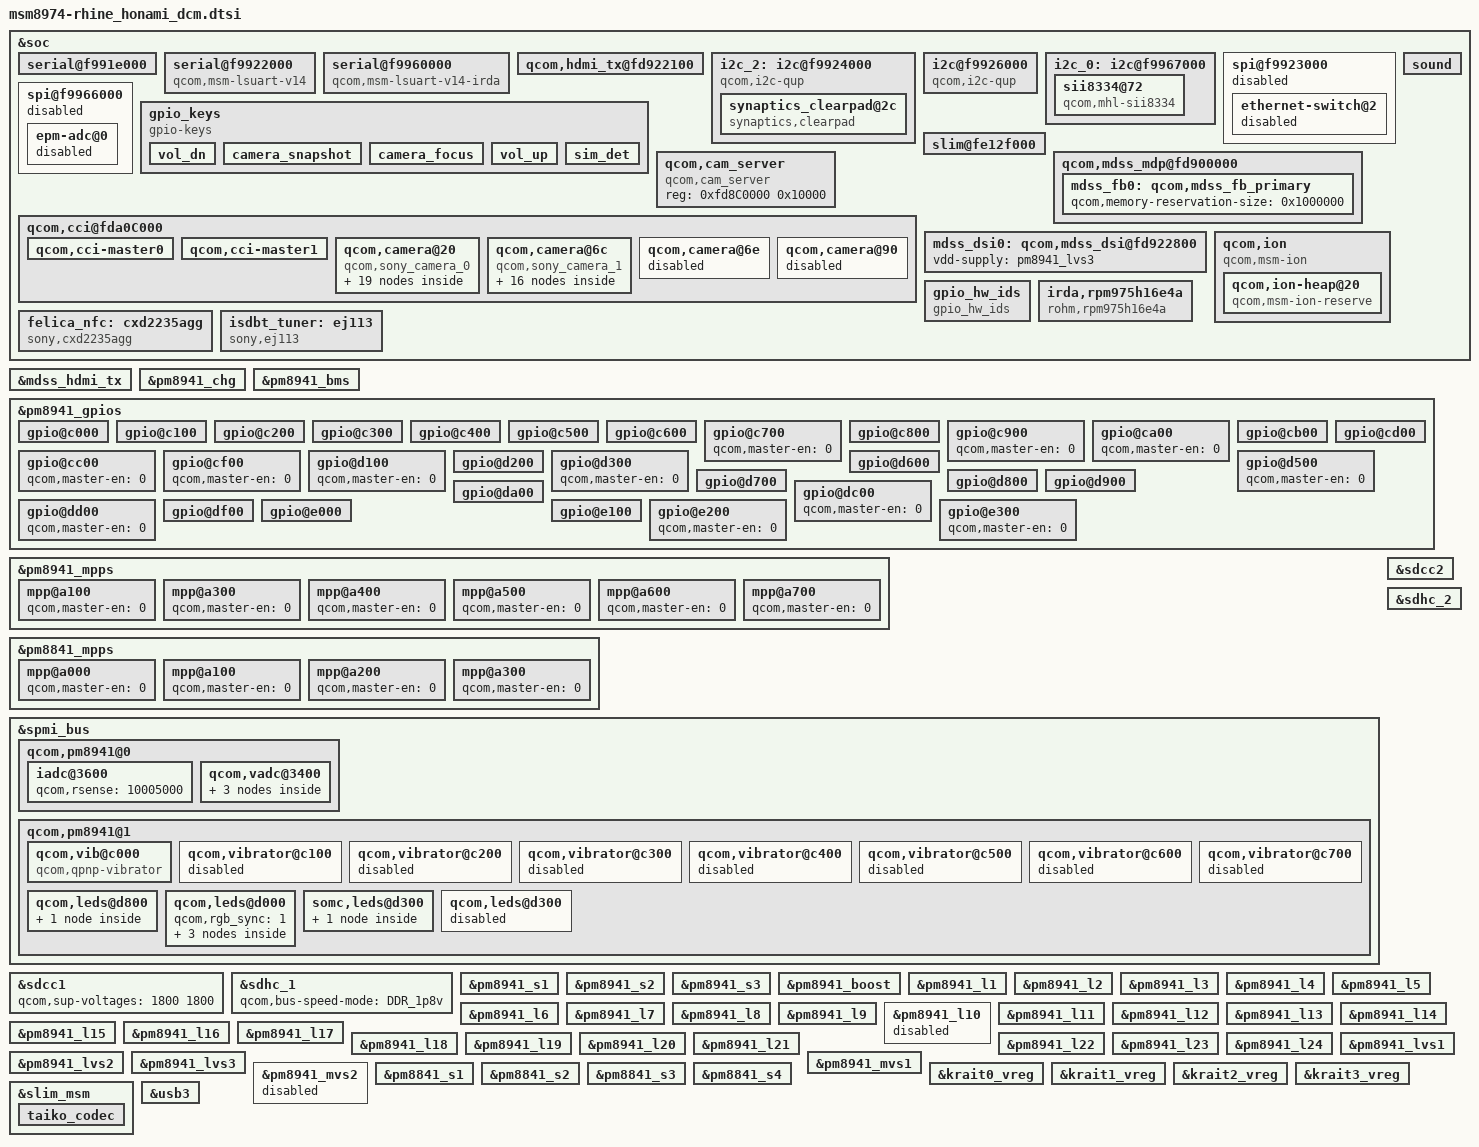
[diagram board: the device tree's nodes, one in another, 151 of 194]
/* arch/arm/boot/dts/msm8974-rhine_honami_dcm.dtsi
 *
 * Copyright (C) 2013 Sony Mobile Communications AB.
 *
 * Author: Yukito Naganuma <Yukito.X.Naganuma@sonymobile.com>
 *
 * This program is free software; you can redistribute it and/or modify
 * it under the terms of the GNU General Public License version 2 and
 * only version 2 as published by the Free Software Foundation.
 *
 * This program is distributed in the hope that it will be useful,
 * but WITHOUT ANY WARRANTY; without even the implied warranty of
 * MERCHANTABILITY or FITNESS FOR A PARTICULAR PURPOSE.  See the
 * GNU General Public License for more details.
 */

&soc {
	/* BLSP1-1 */
	serial@f991e000 {
		status = "ok";
	};

	/* BLSP1-5 */
	serial@f9922000 {
		compatible = "qcom,msm-lsuart-v14";
		reg = <0xf9922000 0x1000>;
		interrupts = <0 112 0>;		/* temporary: interrupt ID is correct??? */
		status = "ok";
	};

	/* BLSP2-3 */
	serial@f9960000 {
		compatible = "qcom,msm-lsuart-v14-irda";
		reg = <0xf9960000 0x1000>;
		interrupts = <0 116 0>;		/* temporary: interrupt ID is correct??? */
		status = "ok";
	};

	qcom,hdmi_tx@fd922100 {
		status = "ok";
	};

	/* BLSP1-1 */
	i2c_2: i2c@f9924000 {
		cell-index = <0>;
		compatible = "qcom,i2c-qup";
		qcom,i2c-bus-freq = <355000>;
		qcom,scl-gpio = <&msmgpio 7 0x00>;
		qcom,sda-gpio = <&msmgpio 6 0x00>;
		status = "ok";
		synaptics_clearpad@2c {
			compatible = "synaptics,clearpad";
			reg = <0x2c>;
			interrupt-parent = <&msmgpio>;
			interrupts = <61 0x2>;
			touch_vdd-supply = <&pm8941_l22>;
			touch_vio-supply = <&pm8941_s3>;
			synaptics,irq_gpio = <&msmgpio 61 0x00>;
			pen_enabled = <0>;
			preset_x_max = <1079>;
			preset_y_max = <1919>;
			preset_n_fingers = <10>;
			preset_n_bytes_per_object = <8>;
			por_delay_after = <200>;
		};
	};

	/* BLSP1-3 */
	i2c@f9926000 {
		cell-index = <1>;
		compatible = "qcom,i2c-qup";
		reg = <0xf9926000 0x1000>;
		#address-cells = <1>;
		#size-cells = <0>;
		reg-names = "qup_phys_addr";
		interrupts = <0 98 0>;
		interrupt-names = "qup_err_intr";
		qcom,i2c-bus-freq = <355000>;
		qcom,i2c-src-freq = <50000000>;
		qcom,master-id = <86>;
		status = "ok";
	};

	/* BLSP2-4 */
	i2c_0: i2c@f9967000 {
		cell-index = <4>;
		qcom,i2c-bus-freq = <355000>;
		status = "ok";
		sii8334@72 {
			compatible = "qcom,mhl-sii8334";
			reg = <0x72>;
			interrupt-parent = <&msmgpio>;
			interrupts = <64 0x2008>;
			mhl-intr-gpio = <&msmgpio 64 0>;
			mhl-pwr-gpio = <&msmgpio 60 0>;
			mhl-rst-gpio = <&msmgpio 16 0>;
			qcom,hdmi-tx-map = <&mdss_hdmi_tx>;
		};
	};

	spi@f9923000 {
		status = "disabled";
		ethernet-switch@2 {
			status = "disabled";
		};
	};

	spi@f9966000 {
		status = "disabled";
		epm-adc@0 {
			status = "disabled";
		};
	};

	gpio_keys {
		compatible = "gpio-keys";
		input-name = "gpio-keys";
		interrupt-parent = <&msmgpio>;
		interrupts = <9 0>;

		vol_dn {
			label = "volume_down";
			gpios = <&pm8941_gpios 2 0x1>;
			linux,input-type = <1>;
			linux,code = <114>;
			gpio-key,wakeup;
			debounce-interval = <15>;
		};

		camera_snapshot {
			label = "camera_snapshot";
			gpios = <&pm8941_gpios 3 0x1>;
			linux,input-type = <1>;
			linux,code = <0x2fe>;
			gpio-key,wakeup;
			debounce-interval = <15>;
		};

		camera_focus {
			label = "camera_focus";
			gpios = <&pm8941_gpios 4 0x1>;
			linux,input-type = <1>;
			linux,code = <0x210>;
			gpio-key,wakeup;
			debounce-interval = <15>;
		};

		vol_up {
			label = "volume_up";
			gpios = <&pm8941_gpios 5 0x1>;
			linux,input-type = <1>;
			linux,code = <115>;
			gpio-key,wakeup;
			debounce-interval = <15>;
		};

		sim_det {
			label = "sim-detection";
			gpios = <&msmgpio 9 0x0>;
			linux,input-type = <5>;
			linux,code = <7>;
			gpio-key,wakeup;
			debounce-interval = <10>;
		};
	};

	slim@fe12f000 {
		/* should be added for eS325 settings? same as taiko_codec? */
		/* or place settings on kernel code? */
	};

	qcom,cam_server {
		compatible = "qcom,cam_server";
		reg = <0xfd8C0000 0x10000>;
		reg-names = "server";
	};

	qcom,cci@fda0C000 {
		qcom,cci-master0 {
			qcom,hw-thigh = <22>;
			qcom,hw-tlow = <33>;
		};

		qcom,cci-master1 {
			qcom,hw-thigh = <22>;
			qcom,hw-tlow = <33>;
		};

		qcom,camera@20 {
			compatible = "qcom,sony_camera_0";
			reg = <0x20 0x0>;
			status = "ok";
			qcom,slave-id = <0x20 0x0 0x0000>;
			qcom,csiphy-sd-index = <0>;
			qcom,csid-sd-index = <0>;
			qcom,mount-angle = <270>;
			qcom,sensor-name = "sony_camera_0";
			cam_vdig-supply = <&pm8941_l3>;
			cam_vana-supply = <&pm8941_l17>;
			cam_vio-supply = <&pm8941_lvs2>;
			cam_vaf-supply = <&pm8941_l23>;
			qcom,cam-vreg-name = "cam_vdig", "cam_vana", "cam_vio",
					     "cam_vaf";
			qcom,cam-vreg-type = <0 0 1 0>;
			qcom,cam-vreg-min-voltage = <1200000 2700000 0 2800000>;
			qcom,cam-vreg-max-voltage = <1200000 2700000 0 2800000>;
			qcom,cam-vreg-op-mode = <105000 85600 0 300000>;
			qcom,gpio-no-mux = <0>;
			gpios = <&msmgpio 15 0>,
				<&msmgpio 94 0>;
			qcom,gpio-reset = <1>;
			qcom,gpio-req-tbl-num = <0 1>;
			qcom,gpio-req-tbl-flags = <1 0>;
			qcom,gpio-req-tbl-label = "CAMIF_MCLK",
						  "CAM_RESET1";
			qcom,gpio-set-tbl-num = <1 1>;
			qcom,gpio-set-tbl-flags = <0 2>;
			qcom,gpio-set-tbl-delay = <1 1000>;
			qcom,csi-lane-assign = <0x4320>;
			qcom,csi-lane-mask = <0x1F>;
			qcom,sensor-position = <0>;
			qcom,sensor-mode = <1>;
			qcom,cci-master = <0>;
			sony,i2c_addr = <0x20>;
			sony,eeprom_addr = <0xA0>;
			sony,eeprom_type = <0>;
			sony,eeprom_max_len = <2048>;
			sony,gpio_af = <0>;
			sony,subdev_code = <0x3007>;

			sony,power_sequence {
				module_names = "GENERIC", "SOI20BS0", "SOI08BS2",
						"SOI13BS2", "SEM13BS1", "SOI13BS9";
				default_module_name = "SOI20BS0";

				GENERIC {
					mount_angle = <270>;
					sensor_rotation = <180>;
					power_off {
						commands =
								"I2C_WRITE",
								"GPIO_RESET",
								"CAM_CLK",
								"CAM_VAF",
								"CAM_VANA",
								"CAM_VIO",
								"CAM_VDIG",
								"EXIT";
						CAM_VDIG =
							<0 0xFFFFFFFF 15>;
						CAM_VIO = <1 0xFFFFFFFF 1>;
						CAM_VANA =
							<2 0xFFFFFFFF 1>;
						CAM_VAF = <3 0xFFFFFFFF 0>;
						GPIO_RESET = <5 0x0 1>;
						CAM_CLK = <6 0xFFFFFFFF 1>;
						I2C_WRITE = <7 0x0100 100>;
						EXIT = <8 0x0 0>;
					};
					power_on {
						commands =
								"CAM_VDIG",
								"CAM_VIO",
								"CAM_VANA",
								"CAM_VAF",
								"GPIO_RESET",
								"CAM_CLK",
								"EXIT";
						CAM_VDIG = <0 1200 1>;
						CAM_VIO = <1 0 1>;
						CAM_VANA = <2 2700 0>;
						CAM_VAF = <3 2800 2>;
						GPIO_RESET = <5 1 1>;
						CAM_CLK = <6 0 1>;
						EXIT = <8 0x0 0>;
					};
				};
				SOI20BS0 {
					mount_angle = <90>;
					sensor_rotation = <0>;
					power_off {
						commands =
								"I2C_WRITE",
								"GPIO_RESET",
								"CAM_CLK",
								"CAM_VAF",
								"CAM_VANA",
								"CAM_VIO",
								"CAM_VDIG",
								"EXIT";
						CAM_VDIG =
							<0 0xFFFFFFFF 15>;
						CAM_VIO = <1 0xFFFFFFFF 1>;
						CAM_VANA =
							<2 0xFFFFFFFF 1>;
						CAM_VAF = <3 0xFFFFFFFF 0>;
						GPIO_RESET = <5 0x0 1>;
						CAM_CLK = <6 0xFFFFFFFF 1>;
						I2C_WRITE = <7 0x0100 100>;
						EXIT = <8 0x0 0>;
					};
					power_on {
						commands =
								"CAM_VDIG",
								"CAM_VIO",
								"CAM_VANA",
								"CAM_VAF",
								"GPIO_RESET",
								"CAM_CLK",
								"EXIT";
						CAM_VDIG = <0 1200 1>;
						CAM_VIO = <1 0 1>;
						CAM_VANA = <2 2700 0>;
						CAM_VAF = <3 2800 2>;
						GPIO_RESET = <5 1 1>;
						CAM_CLK = <6 0 1>;
						EXIT = <8 0x0 0>;
					};
				};
				SOI08BS2 {
					mount_angle = <270>;
					sensor_rotation = <180>;
					power_off {
						commands =
								"I2C_WRITE",
								"GPIO_RESET",
								"CAM_CLK",
								"CAM_VAF",
								"CAM_VANA",
								"CAM_VIO",
								"CAM_VDIG",
								"EXIT";
						CAM_VDIG =
							<0 0xFFFFFFFF 15>;
						CAM_VIO = <1 0xFFFFFFFF 1>;
						CAM_VANA =
							<2 0xFFFFFFFF 1>;
						CAM_VAF = <3 0xFFFFFFFF 0>;
						GPIO_RESET = <5 0x0 1>;
						CAM_CLK = <6 0xFFFFFFFF 1>;
						I2C_WRITE = <7 0x0100 100>;
						EXIT = <8 0x0 0>;
					};
					power_on {
						commands =
								"CAM_VDIG",
								"CAM_VIO",
								"CAM_VANA",
								"CAM_VAF",
								"GPIO_RESET",
								"CAM_CLK",
								"EXIT";
						CAM_VDIG = <0 1200 1>;
						CAM_VIO = <1 0 1>;
						CAM_VANA = <2 2700 0>;
						CAM_VAF = <3 2800 2>;
						GPIO_RESET = <5 1 1>;
						CAM_CLK = <6 0 1>;
						EXIT = <8 0x0 0>;
					};
				};
				SOI13BS2 {
					mount_angle = <270>;
					sensor_rotation = <180>;
					power_off {
						commands =
								"I2C_WRITE",
								"GPIO_RESET",
								"CAM_CLK",
								"CAM_VAF",
								"CAM_VANA",
								"CAM_VIO",
								"CAM_VDIG",
								"EXIT";
						CAM_VDIG =
							<0 0xFFFFFFFF 15>;
						CAM_VIO = <1 0xFFFFFFFF 1>;
						CAM_VANA =
							<2 0xFFFFFFFF 1>;
						CAM_VAF = <3 0xFFFFFFFF 0>;
						GPIO_RESET = <5 0x0 1>;
						CAM_CLK = <6 0xFFFFFFFF 1>;
						I2C_WRITE = <7 0x0100 100>;
						EXIT = <8 0x0 0>;
					};
					power_on {
						commands =
								"CAM_VDIG",
								"CAM_VIO",
								"CAM_VANA",
								"CAM_VAF",
								"GPIO_RESET",
								"CAM_CLK",
								"EXIT";
						CAM_VDIG = <0 1200 1>;
						CAM_VIO = <1 0 1>;
						CAM_VANA = <2 2700 0>;
						CAM_VAF = <3 2800 2>;
						GPIO_RESET = <5 1 1>;
						CAM_CLK = <6 0 1>;
						EXIT = <8 0x0 0>;
					};
				};
				SEM13BS1 {
					mount_angle = <270>;
					sensor_rotation = <180>;
					power_off {
						commands =
								"I2C_WRITE",
								"GPIO_RESET",
								"CAM_CLK",
								"CAM_VAF",
								"CAM_VANA",
								"CAM_VIO",
								"CAM_VDIG",
								"EXIT";
						CAM_VDIG =
							<0 0xFFFFFFFF 15>;
						CAM_VIO = <1 0xFFFFFFFF 1>;
						CAM_VANA =
							<2 0xFFFFFFFF 1>;
						CAM_VAF = <3 0xFFFFFFFF 0>;
						GPIO_RESET = <5 0x0 1>;
						CAM_CLK = <6 0xFFFFFFFF 1>;
						I2C_WRITE = <7 0x0100 100>;
						EXIT = <8 0x0 0>;
					};
					power_on {
						commands =
								"CAM_VDIG",
								"CAM_VIO",
								"CAM_VANA",
								"CAM_VAF",
								"GPIO_RESET",
								"CAM_CLK",
								"EXIT";
						CAM_VDIG = <0 1200 1>;
						CAM_VIO = <1 0 1>;
						CAM_VANA = <2 2700 0>;
						CAM_VAF = <3 2800 2>;
						GPIO_RESET = <5 1 1>;
						CAM_CLK = <6 0 1>;
						EXIT = <8 0x0 0>;
					};
				};
				SOI13BS9 {
					mount_angle = <90>;
					sensor_rotation = <0>;
					power_off {
						commands =
								"I2C_WRITE",
								"GPIO_RESET",
								"CAM_CLK",
								"CAM_VAF",
								"CAM_VANA",
								"CAM_VIO",
								"CAM_VDIG",
								"EXIT";
						CAM_VDIG =
							<0 0xFFFFFFFF 15>;
						CAM_VIO = <1 0xFFFFFFFF 1>;
						CAM_VANA =
							<2 0xFFFFFFFF 1>;
						CAM_VAF = <3 0xFFFFFFFF 0>;
						GPIO_RESET = <5 0x0 1>;
						CAM_CLK = <6 0xFFFFFFFF 1>;
						I2C_WRITE = <7 0x0100 100>;
						EXIT = <8 0x0 0>;
					};
					power_on {
						commands =
								"CAM_VDIG",
								"CAM_VIO",
								"CAM_VANA",
								"CAM_VAF",
								"GPIO_RESET",
								"CAM_CLK",
								"EXIT";
						CAM_VDIG = <0 1200 1>;
						CAM_VIO = <1 0 1>;
						CAM_VANA = <2 2700 0>;
						CAM_VAF = <3 2800 2>;
						GPIO_RESET = <5 1 1>;
						CAM_CLK = <6 0 1>;
						EXIT = <8 0x0 0>;
					};
				};
			};
		};

		qcom,camera@6c {
			compatible = "qcom,sony_camera_1";
			reg = <0x6c 0x0>;
			status = "ok";
			qcom,slave-id = <0x6c 0x0000 0x0000>;
			qcom,csiphy-sd-index = <2>;
			qcom,csid-sd-index = <0>;
			qcom,mount-angle = <270>;
			qcom,sensor-name = "sony_camera_1";
			cam_vdig-supply = <&pm8941_l3>;
			cam_vana-supply = <&pm8941_l17>;
			cam_vio-supply = <&pm8941_lvs2>;
			qcom,cam-vreg-name = "cam_vdig", "cam_vana", "cam_vio";
			qcom,cam-vreg-type = <0 0 1>;
			qcom,cam-vreg-min-voltage = <1200000 2700000 0>;
			qcom,cam-vreg-max-voltage = <1200000 2700000 0>;
			qcom,cam-vreg-op-mode = <105000 85600 0>;
			qcom,gpio-no-mux = <0>;
			gpios = <&msmgpio 17 0>,
				<&msmgpio 18 0>;
			qcom,gpio-reset = <1>;
			qcom,gpio-req-tbl-num = <0 1>;
			qcom,gpio-req-tbl-flags = <1 0>;
			qcom,gpio-req-tbl-label = "CAMIF_MCLK",
						  "CAM_RESET1";
			qcom,gpio-set-tbl-num = <1 1>;
			qcom,gpio-set-tbl-flags = <0 2>;
			qcom,gpio-set-tbl-delay = <1 1000>;
			qcom,csi-lane-assign = <0x4320>;
			qcom,csi-lane-mask = <0x7>;
			qcom,sensor-position = <1>;
			qcom,sensor-mode = <1>;
			qcom,cci-master = <1>;
			sony,i2c_addr = <0x6c>;
			sony,eeprom_addr = <0xA0>;
			sony,eeprom_type = <0>;
			sony,eeprom_max_len = <1024>;
			sony,gpio_af = <0>;
			sony,subdev_code = <0x3007>;

			sony,power_sequence {
				module_names = "GENERIC", "LGI02BN0",
						"SEM02BN0", "LGI02BN1",
						"SEM02BN1";
				default_module_name = "SEM02BN1";

				GENERIC {
					mount_angle = <270>;
					sensor_rotation = <180>;
					power_off {
						commands =
								"I2C_WRITE",
								"GPIO_RESET",
								"CAM_CLK",
								"CAM_VANA",
								"CAM_VIO",
								"CAM_VDIG",
								"EXIT";
						CAM_VDIG =
							<0 0xFFFFFFFF 1>;
						CAM_VIO = <1 0xFFFFFFFF 1>;
						CAM_VANA =
							<2 0xFFFFFFFF 1>;
						GPIO_RESET = <5 0x0 1>;
						CAM_CLK = <6 0xFFFFFFFF 1>;
						I2C_WRITE = <7 0x0100 100>;
						EXIT = <8 0x0 0>;
					};
					power_on {
						commands =
								"CAM_VDIG",
								"CAM_VIO",
								"CAM_VANA",
								"GPIO_RESET",
								"CAM_CLK",
								"EXIT";
						CAM_VDIG = <0 1200 1>;
						CAM_VIO = <1 0 1>;
						CAM_VANA = <2 2700 1>;
						GPIO_RESET = <5 1 1>;
						CAM_CLK = <6 0 1>;
						EXIT = <8 0x0 0>;
					};
				};
				LGI02BN0 {
					mount_angle = <90>;
					sensor_rotation = <0>;
					power_off {
						commands =
								"I2C_WRITE",
								"GPIO_RESET",
								"CAM_CLK",
								"CAM_VANA",
								"CAM_VIO",
								"CAM_VDIG",
								"EXIT";
						CAM_VDIG =
							<0 0xFFFFFFFF 1>;
						CAM_VIO = <1 0xFFFFFFFF 1>;
						CAM_VANA =
							<2 0xFFFFFFFF 1>;
						GPIO_RESET = <5 0x0 1>;
						CAM_CLK = <6 0xFFFFFFFF 1>;
						I2C_WRITE = <7 0x0100 100>;
						EXIT = <8 0x0 0>;
					};
					power_on {
						commands =
								"CAM_VDIG",
								"CAM_VIO",
								"CAM_VANA",
								"GPIO_RESET",
								"CAM_CLK",
								"EXIT";
						CAM_VDIG = <0 1200 1>;
						CAM_VIO = <1 0 1>;
						CAM_VANA = <2 2700 1>;
						GPIO_RESET = <5 1 1>;
						CAM_CLK = <6 0 1>;
						EXIT = <8 0x0 0>;
					};
				};
				SEM02BN0 {
					mount_angle = <90>;
					sensor_rotation = <0>;
					power_off {
						commands =
								"I2C_WRITE",
								"GPIO_RESET",
								"CAM_CLK",
								"CAM_VANA",
								"CAM_VIO",
								"CAM_VDIG",
								"EXIT";
						CAM_VDIG =
							<0 0xFFFFFFFF 1>;
						CAM_VIO = <1 0xFFFFFFFF 1>;
						CAM_VANA =
							<2 0xFFFFFFFF 1>;
						GPIO_RESET = <5 0x0 1>;
						CAM_CLK = <6 0xFFFFFFFF 1>;
						I2C_WRITE = <7 0x0100 100>;
						EXIT = <8 0x0 0>;
					};
					power_on {
						commands =
								"CAM_VDIG",
								"CAM_VIO",
								"CAM_VANA",
								"GPIO_RESET",
								"CAM_CLK",
								"EXIT";
						CAM_VDIG = <0 1200 1>;
						CAM_VIO = <1 0 1>;
						CAM_VANA = <2 2700 1>;
						GPIO_RESET = <5 1 1>;
						CAM_CLK = <6 0 1>;
						EXIT = <8 0x0 0>;
					};
				};
				LGI02BN1 {
					mount_angle = <270>;
					sensor_rotation = <180>;
					power_off {
						commands =
								"I2C_WRITE",
								"GPIO_RESET",
								"CAM_CLK",
								"CAM_VANA",
								"CAM_VIO",
								"CAM_VDIG",
								"EXIT";
						CAM_VDIG =
							<0 0xFFFFFFFF 1>;
						CAM_VIO = <1 0xFFFFFFFF 1>;
						CAM_VANA =
							<2 0xFFFFFFFF 1>;
						GPIO_RESET = <5 0x0 1>;
						CAM_CLK = <6 0xFFFFFFFF 1>;
						I2C_WRITE = <7 0x0100 100>;
						EXIT = <8 0x0 0>;
					};
					power_on {
						commands =
								"CAM_VDIG",
								"CAM_VIO",
								"CAM_VANA",
								"GPIO_RESET",
								"CAM_CLK",
								"EXIT";
						CAM_VDIG = <0 1200 1>;
						CAM_VIO = <1 0 1>;
						CAM_VANA = <2 2700 1>;
						GPIO_RESET = <5 1 1>;
						CAM_CLK = <6 0 1>;
						EXIT = <8 0x0 0>;
					};
				};
				SEM02BN1 {
					mount_angle = <270>;
					sensor_rotation = <180>;
					power_off {
						commands =
								"I2C_WRITE",
								"GPIO_RESET",
								"CAM_CLK",
								"CAM_VANA",
								"CAM_VIO",
								"CAM_VDIG",
								"EXIT";
						CAM_VDIG =
							<0 0xFFFFFFFF 1>;
						CAM_VIO = <1 0xFFFFFFFF 1>;
						CAM_VANA =
							<2 0xFFFFFFFF 1>;
						GPIO_RESET = <5 0x0 1>;
						CAM_CLK = <6 0xFFFFFFFF 1>;
						I2C_WRITE = <7 0x0100 100>;
						EXIT = <8 0x0 0>;
					};
					power_on {
						commands =
								"CAM_VDIG",
								"CAM_VIO",
								"CAM_VANA",
								"GPIO_RESET",
								"CAM_CLK",
								"EXIT";
						CAM_VDIG = <0 1200 1>;
						CAM_VIO = <1 0 1>;
						CAM_VANA = <2 2700 1>;
						GPIO_RESET = <5 1 1>;
						CAM_CLK = <6 0 1>;
						EXIT = <8 0x0 0>;
					};
				};
			};
		};

		/* disable Qualcomm camera sensors */
		qcom,camera@6e {
			status = "disabled";
		};

		qcom,camera@90 {
			status = "disabled";
		};
	};

	qcom,mdss_mdp@fd900000 {
		mdss_fb0: qcom,mdss_fb_primary {
			qcom,memory-reservation-size = <0x1000000>; /* size 16MB */
		};
	};

	mdss_dsi0: qcom,mdss_dsi@fd922800 {
		vdd-supply = <&pm8941_lvs3>;
	};

	sound {
		qcom,audio-routing =
			"RX_BIAS", "MCLK",
			"LDO_H", "MCLK",
			"Ext Spk Bottom Pos", "LINEOUT1",
			"Ext Spk Bottom Neg", "LINEOUT3",
			"Ext Spk Top Pos", "LINEOUT2",
			"Ext Spk Top Neg", "LINEOUT4",
			"AMIC1", "MIC BIAS1 External",
			"MIC BIAS1 External", "Handset Mic",
			"AMIC2", "MIC BIAS2 External",
			"MIC BIAS2 External", "Headset Mic",
			"AMIC3", "MIC BIAS3 External",
			"MIC BIAS3 External", "ANCLeft Headset Mic",
			"AMIC4", "MIC BIAS1 External",
			"MIC BIAS1 External", "Handset Mic",
			"AMIC5", "MIC BIAS1 External",
			"MIC BIAS1 External", "Secondary Mic",
			"AMIC6", "MIC BIAS4 External",
			"MIC BIAS4 External", "Handset FB ANC Mic";
	};

	qcom,ion {
		compatible = "qcom,msm-ion";

		qcom,ion-heap@20 { /* CAMERA HEAP */
			compatible = "qcom,msm-ion-reserve";
			reg = <20>;
			qcom,heap-align = <0x1000>;
			qcom,memory-reservation-type = "EBI1"; /* reserve EBI memory */
			qcom,memory-reservation-size = <0x6400000>;
		};
	};

	gpio_hw_ids {
		compatible = "gpio_hw_ids";

		gpios = <&pm8941_gpios 1 0>,
			<&pm8941_gpios 6 0>,
			<&pm8941_gpios 7 0>,
			<&pm8941_gpios 14 0>;
	};

	felica_nfc: cxd2235agg {
		compatible = "sony,cxd2235agg";
		interrupt-parent = <&msmgpio>;
		interrupts = <78 0x2003>, <77 0x2003>, <59 0x2003>; /* INTU, RFS, INT */
		gpios = <&pm8941_gpios 34 0>, /* LOCK */
			<&pm8941_gpios 33 0>, /* FF */
			<&pm8941_gpios 23 0>, /* PON */
			<&pm8941_gpios 24 0>, /* LDO EN */
			<&msmgpio 78 0>, /* INTU */
			<&msmgpio 57 0>, /* HSEL */
			<&msmgpio 77 0>, /* RFS */
			<&msmgpio 59 0>, /* INT */
			<&msmgpio 76 0>, /* PVDD */
			<&msmgpio 27 0>, /* TX */
			<&msmgpio 28 0>; /* RX */
	};

	irda,rpm975h16e4a {
		compatible = "rohm,rpm975h16e4a";
		gpios = <&msmgpio 53 0>, /* TX */
			<&msmgpio 54 0>; /* RX */
		pwdown_gpio = <&pm8941_gpios 25 0>;
		rpm975h16e4a_vcc-supply = <&pm8941_l18>;
		rpm975h16e4a_vio-supply = <&pm8941_lvs1>;
	};

	isdbt_tuner: ej113 {
		compatible = "sony,ej113";
		interrupt-parent = <&msmgpio>;
		interrupts = <68 0>;
		gpios = <&pm8941_gpios 26 0>, /* ANT_POWER */
			<&pm8941_gpios 32 0>, /* ANT_SWITCH */
			<&msmgpio 14 0>, /* TUNER_POWER */
			<&msmgpio 13 0>, /* TUNER_RESET */
			<&msmgpio 68 0>; /* TUNER_INT */
	};
};

&mdss_hdmi_tx {
	/* rhine doesn't use hpd-5v */
	qcom,hdmi-tx-supply-names = "hpd-gdsc", "core-vdda", "core-vcc";
	qcom,hdmi-tx-min-voltage-level = <0 1800000 1800000>;
	qcom,hdmi-tx-max-voltage-level = <0 1800000 1800000>;
	qcom,hdmi-tx-peak-current = <0 1800000 0>;
};

&pm8941_chg {
	qcom,vddmax-mv = <4350>;
	qcom,vddsafe-mv = <4400>;
	qcom,ibatmax-ma = <1500>;
	qcom,ibatterm-ma = <150>;
	qcom,ibatsafe-ma = <1500>;
	qcom,maxinput-dc-ma = <1800>;
	qcom,maxinput-usb-ma = <1500>;
	qcom,cool-bat-mv = <4350>;
	qcom,ibatmax-warm-ma = <900>;
	qcom,warm-bat-mv = <4200>;
	qcom,ibatmax-cool-ma = <900>;
	qcom,vbatdet-delta-mv = <20>;
	qcom,vbatdet-delta-soc = <1>;
	qcom,thermal-mitigation = <1500 1500 1100 900 700 500 300 200 100 0>;
	qcom,tchg-mins = <512>;
};

&pm8941_bms {
	qcom,r-sense-uohm = <10005>;
	qcom,v-cutoff-uv = <3200000>;
	qcom,max-voltage-uv = <4350000>;
	qcom,r-conn-mohm = <0>;
	qcom,low-soc-calculate-soc-threshold = <5>;
	qcom,low-soc-calculate-soc-ms = <1000>;
	qcom,calculate-soc-ms = <30000>;
	qcom,use-external-rsense = <1>;
	qcom,batt-type = <3>;
	qcom,shutdown-soc-valid-limit = <40>;
	qcom,clamp-soc-max-count = <2>;
	qcom,enable-fcc-learning;
	qcom,min-fcc-learning-soc = <20>;
	qcom,min-fcc-ocv-pc = <30>;
	qcom,min-fcc-learning-samples = <5>;
	qcom,fcc-resolution = <10>;
};

&pm8941_gpios {
	/* GPIO_1: HW_ID_0 */
	gpio@c000 {
		qcom,src-sel = <0>;		/* GPIO */
		qcom,mode = <0>;		/* In */
		qcom,vin-sel = <2>;		/* S3 */
		qcom,pull = <5>;		/* NP */
		qcom,master-en = <1>;		/* Enable */
		status = "ok";
	};

	/* GPIO_2: VOL_DN */
	gpio@c100 {
		qcom,src-sel = <0>;		/* GPIO */
		qcom,mode = <0>;		/* In */
		qcom,vin-sel = <2>;		/* S3 */
		qcom,pull = <0>;		/* PU */
		qcom,master-en = <1>;		/* Enable */
		status = "ok";
	};

	/* GPIO_3: SNAPSHOT */
	gpio@c200 {
		qcom,src-sel = <0>;		/* GPIO */
		qcom,mode = <0>;		/* In */
		qcom,vin-sel = <2>;		/* S3 */
		qcom,pull = <0>;		/* PU */
		qcom,master-en = <1>;		/* Enable */
		status = "ok";
	};

	/* GPIO_4: FOCUS */
	gpio@c300 {
		qcom,src-sel = <0>;		/* GPIO */
		qcom,mode = <0>;		/* In */
		qcom,vin-sel = <2>;		/* S3 */
		qcom,pull = <0>;		/* PU */
		qcom,master-en = <1>;		/* Enable */
		status = "ok";
	};

	/* GPIO_5: VOL_UP */
	gpio@c400 {
		qcom,src-sel = <0>;		/* GPIO */
		qcom,mode = <0>;		/* In */
		qcom,vin-sel = <2>;		/* S3 */
		qcom,pull = <0>;		/* PU */
		qcom,master-en = <1>;		/* Enable */
		status = "ok";
	};

	/* GPIO_6: HW_ID_1 */
	gpio@c500 {
		qcom,src-sel = <0>;		/* GPIO */
		qcom,mode = <0>;		/* In */
		qcom,vin-sel = <2>;		/* S3 */
		qcom,pull = <5>;		/* NP */
		qcom,master-en = <1>;		/* Enable */
		status = "ok";
	};

	/* GPIO_7: HW_ID_2 */
	gpio@c600 {
		qcom,src-sel = <0>;		/* GPIO */
		qcom,mode = <0>;		/* In */
		qcom,vin-sel = <2>;		/* S3 */
		qcom,pull = <5>;		/* NP */
		qcom,master-en = <1>;		/* Enable */
		status = "ok";
	};

	/* GPIO_8: NC (EXT_BATFET_N) */
	gpio@c700 {
		qcom,master-en = <0>;		/* Disable */
		status = "ok";
	};

	/* GPIO_9: RF_ID_EN */
	gpio@c800 {
		qcom,src-sel = <0>;		/* GPIO */
		qcom,mode = <1>;		/* Out */
		qcom,output-type = <0>;		/* CMOS */
		qcom,vin-sel = <2>;		/* S3 */
		qcom,out-strength = <3>;	/* High */
		qcom,invert = <0>;		/* Low */
		qcom,master-en = <1>;		/* Enable */
		status = "ok";
	};

	/* GPIO_10: NC (FCHG_CNT) */
	gpio@c900 {
		qcom,master-en = <0>;		/* Disable */
		status = "ok";
	};

	/* GPIO_11: NC (AUD_DSP_PWR_EN) */
	gpio@ca00 {
		qcom,master-en = <0>;		/* Disable */
		status = "ok";
	};

	/* GPIO_12: RF_ID_EXTENTION */
	gpio@cb00 {
		qcom,src-sel = <0>;		/* GPIO */
		qcom,mode = <0>;		/* In */
		qcom,vin-sel = <2>;		/* S3 */
		qcom,pull = <4>;		/* PD */
		qcom,master-en = <1>;		/* Enable */
		status = "ok";
	};

	/* GPIO_13: NC (TUNER_STATUS0) */
	gpio@cc00 {
		qcom,master-en = <0>;		/* Disable */
		status = "ok";
	};

	/* GPIO_14: HW_ID_3 */
	gpio@cd00 {
		qcom,src-sel = <0>;		/* GPIO */
		qcom,mode = <0>;		/* In */
		qcom,vin-sel = <2>;		/* S3 */
		qcom,pull = <4>;		/* PD */
		qcom,master-en = <1>;		/* Enable */
		status = "ok";
	};

	/* GPIO_15: DIVCLK1_CODEC */
	/* Follow QCT */

	/* GPIO_16: NC */
	gpio@cf00 {
		qcom,master-en = <0>;		/* Disable */
		status = "ok";
	};

	/* GPIO_17: (DIVCLK3) QPA_XO */
	/* Follow QCT */

	/* GPIO_18: NC (TUNER_STATUS1) */
	gpio@d100 {
		qcom,master-en = <0>;		/* Disable */
		status = "ok";
	};

	/* GPIO_19: DISP_RESET_N */
	gpio@d200 {
		qcom,src-sel = <0>;		/* GPIO */
		qcom,mode = <1>;		/* Out */
		qcom,output-type = <0>;		/* CMOS */
		qcom,vin-sel = <2>;		/* S3 */
		qcom,out-strength = <1>;	/* Low */
		qcom,invert = <0>;		/* Low */
		qcom,master-en = <1>;		/* Enable */
		status = "ok";
	};

	/* GPIO_20: NC (IR_LEVEL_EN) */
	gpio@d300 {
		qcom,master-en = <0>;		/* Disable */
		status = "ok";
	};

	/* GPIO_21: BOOST_BYP_EN */
	/* Follow QCT */

	/* GPIO_22: NC (HS_DET) */
	gpio@d500 {
		qcom,master-en = <0>;		/* Disable */
		status = "ok";
	};

	/* GPIO_23: FELICA_PON */
	gpio@d600 {
		qcom,src-sel = <0>;		/* GPIO */
		qcom,mode = <1>;		/* Out */
		qcom,output-type = <0>;		/* CMOS */
		qcom,vin-sel = <2>;		/* S3 */
		qcom,out-strength = <1>;	/* Low */
		qcom,invert = <0>;		/* Low */
		qcom,master-en = <1>;		/* Enable */
		status = "ok";
	};

	/* GPIO_24: NFC_EXT_LDO_EN */
	gpio@d700 {
		qcom,src-sel = <0>;		/* GPIO */
		qcom,mode = <1>;		/* Out */
		qcom,output-type = <0>;		/* CMOS */
		qcom,vin-sel = <2>;		/* S3 */
		qcom,out-strength = <1>;	/* Low */
		qcom,invert = <0>;		/* Low */
		qcom,master-en = <1>;		/* Enable */
		status = "ok";
	};

	/* GPIO_25: IR_RESET */
	gpio@d800 {
		qcom,src-sel = <0>;		/* GPIO */
		qcom,mode = <1>;		/* Out */
		qcom,output-type = <0>;		/* CMOS */
		qcom,vin-sel = <2>;		/* S3 */
		qcom,out-strength = <1>;	/* Low */
		qcom,invert = <0>;		/* Low */
		qcom,master-en = <1>;		/* Enable */
		status = "ok";
	};

	/* GPIO_26: TUNER_ANT_SW_EN */
	gpio@d900 {
		qcom,src-sel = <0>;		/* GPIO */
		qcom,mode = <1>;		/* Out */
		qcom,output-type = <0>;		/* CMOS */
		qcom,vin-sel = <2>;		/* S3 */
		qcom,out-strength = <1>;	/* Low */
		qcom,invert = <0>;		/* Low */
		qcom,master-en = <1>;		/* Enable */
		status = "ok";
	};

	/* GPIO_27: FLASH_LED_NOW */
	gpio@da00 {
		qcom,src-sel = <2>;		/* Alternate function 1 */
		qcom,mode = <0>;		/* In */
		qcom,vin-sel = <2>;		/* S3 */
		qcom,pull = <4>;		/* PD */
		qcom,master-en = <1>;		/* Enable */
		status = "ok";
	};

	/* GPIO_28: TX_GTR_THRES */
	/* Follow QCT */

	/* GPIO_29: NC */
	gpio@dc00 {
		qcom,master-en = <0>;		/* Disable */
		status = "ok";
	};

	/* GPIO_30: NC */
	gpio@dd00 {
		qcom,master-en = <0>;		/* Disable */
		status = "ok";
	};

	/* GPIO_31: BATT_REM_ALERM */
	/* Follow QCT */

	/* GPIO_32: TUNER_ANT_SW1 */
	gpio@df00 {
		qcom,src-sel = <0>;		/* GPIO */
		qcom,mode = <1>;		/* Out */
		qcom,output-type = <0>;		/* CMOS */
		qcom,vin-sel = <2>;		/* S3 */
		qcom,out-strength = <1>;	/* Low */
		qcom,invert = <0>;		/* Low */
		qcom,master-en = <1>;		/* Enable */
		status = "ok";
	};

	/* GPIO_33: FELICA_FF */
	gpio@e000 {
		qcom,src-sel = <0>;		/* GPIO */
		qcom,mode = <1>;		/* Out */
		qcom,output-type = <0>;		/* CMOS */
		qcom,vin-sel = <0>;		/* VPH */
		qcom,out-strength = <1>;	/* Low */
		qcom,invert = <0>;		/* Low */
		qcom,master-en = <1>;		/* Enable */
		status = "ok";
	};

	/* GPIO_34: FELICA_LOCK */
	gpio@e100 {
		qcom,src-sel = <0>;		/* GPIO */
		qcom,mode = <0>;		/* In */
		qcom,vin-sel = <2>;		/* S3 */
		qcom,pull = <5>;		/* NP */
		qcom,master-en = <1>;		/* Enable */
		status = "ok";
	};

	/* GPIO_35: NC (Reserved for ANC_HS_DET) */
	gpio@e200 {
		qcom,master-en = <0>;		/* Disable */
		status = "ok";
	};

	/* GPIO_36: NC */
	gpio@e300 {
		qcom,master-en = <0>;		/* Disable */
		status = "ok";
	};
};

&pm8941_mpps {
	/* MPP_1: SDC_UIM_VBIAS */
	/* Follow QCT */

	/* MPP_2: NC */
	mpp@a100 {
		qcom,master-en = <0>;		/* Disable */
		status = "ok";
	};

	/* MPP_3: TXDAC0_VREF */
	/* Follow QCT */

	/* MPP_4: NC */
	mpp@a300 {
		qcom,master-en = <0>;		/* Disable */
		status = "ok";
	};

	/* MPP_5: NC */
	mpp@a400 {
		qcom,master-en = <0>;		/* Disable */
		status = "ok";
	};

	/* MPP_6: NC (ACC_ADC) */
	mpp@a500 {
		qcom,master-en = <0>;		/* Disable */
		status = "ok";
	};

	/* MPP_7: RF_ID */
	mpp@a600 {
		qcom,master-en = <0>;		/* Disable */
		status = "ok";
	};

	/* MPP_8: NC */
	mpp@a700 {
		qcom,master-en = <0>;		/* Disable */
		status = "ok";
	};
};

&pm8841_mpps {
	/* MPP_1: NC (LMU_EN) */
	mpp@a000 {
		qcom,master-en = <0>;		/* Disable */
		status = "ok";
	};

	/* MPP_2: NC (FLASH_DR_RST_N) */
	mpp@a100 {
		qcom,master-en = <0>;		/* Disable */
		status = "ok";
	};

	/* MPP_3: NC */
	mpp@a200 {
		qcom,master-en = <0>;		/* Disable */
		status = "ok";
	};

	/* MPP_4: NC */
	mpp@a300 {
		qcom,master-en = <0>;		/* Disable */
		status = "ok";
	};
};

&spmi_bus {
	qcom,pm8941@0 {
		iadc@3600 {
			qcom,rsense = <10005000>;
		};
	};

	qcom,pm8941@1 {
		qcom,vib@c000 {
			status = "okay";
			compatible = "qcom,qpnp-vibrator";
			reg = <0xc000 0x100>;
			label = "vibrator";
			qcom,qpnp-vib-vtg-level-mV = <3100>;
		};

		qcom,vibrator@c100 {
			status = "disabled";
		};

		qcom,vibrator@c200 {
			status = "disabled";
		};

		qcom,vibrator@c300 {
			status = "disabled";
		};

		qcom,vibrator@c400 {
			status = "disabled";
		};

		qcom,vibrator@c500 {
			status = "disabled";
		};

		qcom,vibrator@c600 {
			status = "disabled";
		};

		qcom,vibrator@c700 {
			status = "disabled";
		};

		qcom,leds@d800 {
			status = "okay";
			qcom,wled_0 {
				label = "wled";
				linux,name = "wled:backlight";
				linux,default-trigger = "bkl-trigger";
				qcom,cs-out-en = <1>;
				qcom,cabc-en = <1>;
				qcom,op-fdbck = <0>;
				qcom,default-state = "on";
				qcom,max-current = <20>;
				qcom,ctrl-delay-us = <0>;
				qcom,boost-curr-lim = <3>;
				qcom,cp-sel = <0>;
				qcom,switch-freq = <2>;
				qcom,ovp-val = <2>;
				qcom,num-strings = <2>;
				qcom,id = <0>;
			};
		};

		qcom,leds@d000 {
			status = "okay";
			qcom,rgb_sync = <1>;

			qcom,rgb_0 {
				label = "rgb";
				linux,name = "led:rgb_red";
				qcom,mode = "pwm";
				qcom,pwm-channel = <6>;
				qcom,pwm-us = <1000>;
				qcom,pwm-max-value = <304>;
				qcom,max-current = <12>;
				qcom,default-state = "off";
				qcom,id = <3>;
				linux,default-trigger = "none";
			};

			qcom,rgb_1 {
				label = "rgb";
				linux,name = "led:rgb_green";
				qcom,mode = "pwm";
				qcom,pwm-channel = <5>;
				qcom,pwm-us = <1000>;
				qcom,pwm-max-value = <511>;
				qcom,max-current = <12>;
				qcom,default-state = "off";
				qcom,id = <4>;
				linux,default-trigger = "none";
			};

			qcom,rgb_2 {
				label = "rgb";
				linux,name = "led:rgb_blue";
				qcom,mode = "pwm";
				qcom,pwm-channel = <4>;
				qcom,pwm-us = <1000>;
				qcom,pwm-max-value = <368>;
				qcom,max-current = <12>;
				qcom,default-state = "off";
				qcom,id = <5>;
				linux,default-trigger = "none";
			};
		};

		somc,leds@d300 {
			status = "okay";
			label = "flash";
			somc,headroom = <2>;
			somc,clamp-curr-mA = <13>;
			somc,startup-dly = <3>;
			somc,hw-strobe-config = <3>;
			somc,mask-enable = <1>;
			somc,vph-pwr-droop {
				somc,enable = <0>;
				somc,threshold = <0>;
				somc,debounce-time = <2>;
			};
		};

		qcom,leds@d300 {
			status = "disabled";
		};
	};
};

&sdcc1 {
	qcom,sup-voltages = <1800 1800>;
};

&sdcc2 {
	#address-cells = <0>;
	interrupt-parent = <&sdcc2>;
	interrupts = <0 1 2>;
	#interrupt-cells = <1>;
	interrupt-map-mask = <0xffffffff>;
	interrupt-map = <0 &intc 0 125 0
			1 &intc 0 220 0
			2 &msmgpio 62 0x3>;
	interrupt-names = "core_irq", "bam_irq", "status_irq";
	cd-gpios = <&msmgpio 62 0x1>;
	qcom,sdcc-vdd-io-voltage_level = <2950000 2950000>;
	qcom,pad-drv-on = <0x4 0x2 0x2>; /* 10mA, 6mA, 6mA */
	qcom,bus-speed-mode = "SDR12", "SDR25", "SDR50", "DDR50";
	qcom,current-limit = <400>;
};

&sdhc_1 {
	qcom,bus-speed-mode = "DDR_1p8v";
};

&sdhc_2 {
	qcom,pad-drv-on = <0x4 0x2 0x2>; /* 10mA, 6mA, 6mA */
	qcom,vdd-current-level = <400000 400000>;
};

/* Regulator config */
&pm8941_s1 {
	status = "ok";
};

&pm8941_s2 {
	status = "ok";
};

&pm8941_s3 {
	status = "ok";
};

&pm8941_boost { /* VREG_5V */
	status = "ok";
};

&pm8941_l1 {
	status = "ok";
};

&pm8941_l2 {
	status = "ok";
};

&pm8941_l3 {
	regulator-min-microvolt = <1200000>;
	regulator-max-microvolt = <1200000>;
	qcom,init-voltage = <1200000>;
	qcom,init-ldo-mode = <1>;
	status = "ok";
};

&pm8941_l4 {
	status = "ok";
};

&pm8941_l5 {
	status = "ok";
};

&pm8941_l6 {
	status = "ok";
};

&pm8941_l7 {
	status = "ok";
};

&pm8941_l8 {
	status = "ok";
};

&pm8941_l9 {
	status = "ok";
};

&pm8941_l10 {
	status = "disabled";
};

&pm8941_l11 {
	status = "ok";
};

&pm8941_l12 {
	status = "ok";
};

&pm8941_l13 {
	status = "ok";
};

&pm8941_l14 {
	status = "ok";
};

&pm8941_l15 {
	status = "ok";
};

&pm8941_l16 {
	status = "ok";
};

&pm8941_l17 {
	regulator-min-microvolt = <2700000>;
	regulator-max-microvolt = <2700000>;
	qcom,init-voltage = <2700000>;
	qcom,init-ldo-mode = <1>;
	status = "ok";
};

&pm8941_l18 {
	regulator-min-microvolt = <2850000>;
	regulator-max-microvolt = <2850000>;
	qcom,init-voltage = <2850000>;
	status = "ok";
};

&pm8941_l19 {
	regulator-min-microvolt = <3300000>;
	regulator-max-microvolt = <3300000>;
	qcom,init-voltage = <3300000>;
	status = "ok";
};

&pm8941_l20 {
	regulator-min-microvolt = <2950000>;
	regulator-max-microvolt = <2950000>;
	qcom,init-voltage = <2950000>;
	status = "ok";
};

&pm8941_l21 {
	regulator-min-microvolt = <2950000>;
	regulator-max-microvolt = <2950000>;
	qcom,init-voltage = <2950000>;
	status = "ok";
};

&pm8941_l22 {
	regulator-min-microvolt = <3000000>;
	regulator-max-microvolt = <3000000>;
	qcom,init-voltage = <3000000>;
	status = "ok";
};

&pm8941_l23 {
	regulator-min-microvolt = <2800000>;
	regulator-max-microvolt = <2800000>;
	qcom,init-voltage = <2800000>;
	qcom,init-ldo-mode = <1>;
	status = "ok";
};

&pm8941_l24 {
	status = "ok";
};

&pm8941_lvs1 {
	status = "ok";
};

&pm8941_lvs2 {
	status = "ok";
};

&pm8941_lvs3 {
	status = "ok";
};

&pm8941_mvs1 { /* VREG_OTG */
	status = "ok";
};

&pm8941_mvs2 { /* VREG_HDMI */
	status = "disabled";
};

&pm8841_s1 {
	status = "ok";
};

&pm8841_s2 {
	status = "ok";
};

&pm8841_s3 {
	status = "ok";
};

&pm8841_s4 {
	status = "ok";
};

&krait0_vreg { /* PM8821 VREG_S5 */
	status = "ok";
};

&krait1_vreg { /* PM8821 VREG_S6 */
	status = "ok";
};

&krait2_vreg { /* PM8821 VREG_S7 */
	status = "ok";
};

&krait3_vreg { /* PM8821 VREG_S8 */
	status = "ok";
};

&slim_msm {
	taiko_codec {
		qcom,cdc-micbias-ldoh-v = <0x3>;
		qcom,cdc-micbias-cfilt1-mv = <2700>;
		qcom,cdc-micbias-cfilt2-mv = <2700>;
		qcom,cdc-micbias-cfilt3-mv = <2700>;
		qcom,cdc-micbias1-cfilt-sel = <0x1>;
		qcom,cdc-micbias2-cfilt-sel = <0x1>;
		qcom,cdc-micbias3-cfilt-sel = <0x1>;
		qcom,cdc-micbias4-cfilt-sel = <0x1>;
	};
};

&usb3 {
	qcom,dwc-hsphy-init = <0x00D0CC27>;
	interrupt-parent = <&usb3>;
	interrupts = <0 1>;
	#interrupt-cells = <1>;
	interrupt-map-mask = <0x0 0xffffffff>;
	interrupt-map = <0x0 0 &intc 0 133 0
			 0x0 1 &spmi_bus 0x0 0x0 0x9 0x0>;
	interrupt-names = "hs_phy_irq", "pmic_id_irq";
	qcom,misc-ref = <&pm8941_misc>;
};

&spmi_bus {
	qcom,pm8941@0 {
		qcom,vadc@3400 {
			chan@30 {
				qcom,hw-settle-time = <15>;
			};

			chan@8 {
				qcom,hw-settle-time = <15>;
			};

			chan@6 {
				qcom,hw-settle-time = <15>;
			};
		};
	};
};
